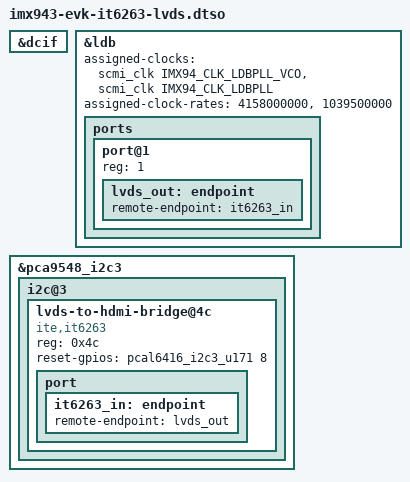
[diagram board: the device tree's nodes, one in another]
// SPDX-License-Identifier: (GPL-2.0+ OR MIT)
/*
 * Copyright 2025 NXP
 */

/dts-v1/;
/plugin/;

#include <dt-bindings/gpio/gpio.h>
#include "imx94-clock.h"

&dcif {
	status = "okay";
};

&ldb {
	#address-cells = <1>;
	#size-cells = <0>;
	assigned-clocks = <&scmi_clk IMX94_CLK_LDBPLL_VCO>,
			  <&scmi_clk IMX94_CLK_LDBPLL>;
	assigned-clock-rates = <4158000000>, <1039500000>;
	status = "okay";

	ports {
		#address-cells = <1>;
		#size-cells = <0>;

		status = "okay";

		port@1 {
			reg = <1>;

			lvds_out: endpoint {
				remote-endpoint = <&it6263_in>;
			};
		};
	};
};

&pca9548_i2c3 {
	i2c@3 {
		#address-cells = <1>;
		#size-cells = <0>;

		lvds-to-hdmi-bridge@4c {
			compatible = "ite,it6263";
			reg = <0x4c>;
			reset-gpios = <&pcal6416_i2c3_u171 8 GPIO_ACTIVE_HIGH>;

			port {
				it6263_in: endpoint {
					remote-endpoint = <&lvds_out>;
				};
			};
		};
	};
};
